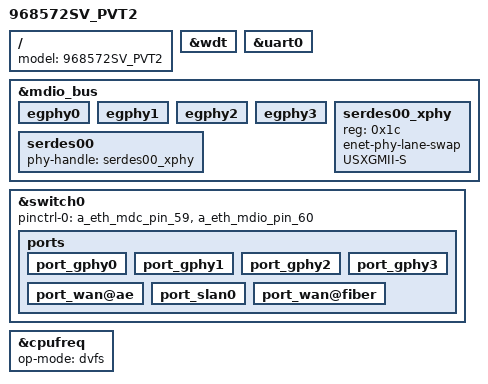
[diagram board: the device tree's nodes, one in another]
#include "inc/968370SV.dtsi"

/ {
    model = "968572SV_PVT2";
};

&wdt {
	status = "okay";
};
&uart0 {
	status = "okay";
};

&mdio_bus {
    egphy0 {
        status = "okay";
    };
    egphy1 {
        status = "okay";
    };
    egphy2 {
        status = "okay";
    };
    egphy3 {
        status = "okay";
    };
    serdes00_xphy {
        reg = <0x1c>;
        enet-phy-lane-swap;
        USXGMII-S;
        status = "okay";
    };
    serdes00 {
        phy-handle = <&serdes00_xphy>;
        status = "okay";
    };
};

&switch0 {
    pinctrl-names = "default";
    pinctrl-0 = <&a_eth_mdc_pin_59 &a_eth_mdio_pin_60>;

    ports {
        port_gphy0 {
            status = "okay";
        };
        port_gphy1 {
            status = "okay";
        };
        port_gphy2 {
            status = "okay";
        };
        port_gphy3 {
            status = "okay";
        };
        port_wan@ae {
            status = "okay";
        };
        port_slan0 {
            status = "okay";
        };
        port_wan@fiber {
            status = "okay";
        };
    };
};

&cpufreq {
    op-mode = "dvfs";
};
